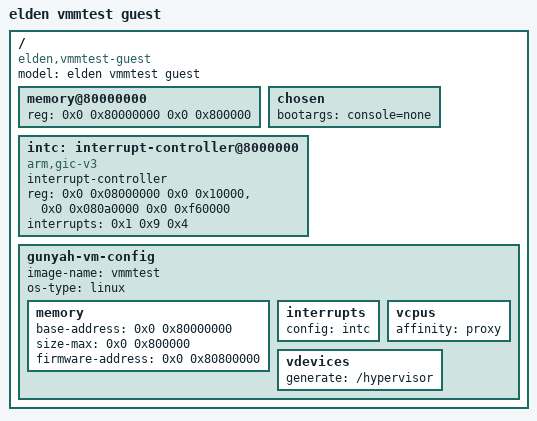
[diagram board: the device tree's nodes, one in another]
/dts-v1/;
/* v5 = v2 + firmware-address (crosvm create_fdt sets it when a
 * ProtectedFirmwareRegion exists; value must equal the gpa passed to
 * SET_FW_CONFIG — here fw_gpa = 0x80800000). */
/ {
	#address-cells = <2>;
	#size-cells = <2>;
	compatible = "elden,vmmtest-guest";
	model = "elden vmmtest guest";

	memory@80000000 {
		device_type = "memory";
		reg = <0x0 0x80000000 0x0 0x800000>;
	};

	chosen {
		bootargs = "console=none";
	};

	intc: interrupt-controller@8000000 {
		compatible = "arm,gic-v3";
		#interrupt-cells = <3>;
		#address-cells = <2>;
		#size-cells = <2>;
		ranges;
		interrupt-controller;
		reg = <0x0 0x08000000 0x0 0x10000>,
		      <0x0 0x080a0000 0x0 0xf60000>;
		interrupts = <0x1 0x9 0x4>;
	};

	gunyah-vm-config {
		image-name = "vmmtest";
		os-type = "linux";

		memory {
			#address-cells = <2>;
			#size-cells = <2>;
			base-address = <0x0 0x80000000>;
			size-max = <0x0 0x800000>;
			firmware-address = <0x0 0x80800000>;
		};

		interrupts {
			config = <&intc>;
		};

		vcpus {
			affinity = "proxy";
		};

		vdevices {
			generate = "/hypervisor";
		};
	};
};
